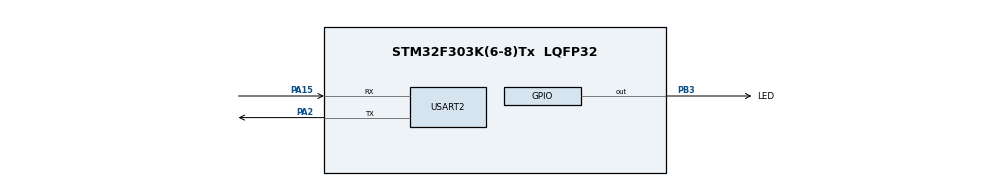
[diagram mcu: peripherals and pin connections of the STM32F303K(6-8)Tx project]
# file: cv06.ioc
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Mcu.Family=STM32F3
Mcu.Name=STM32F303K(6-8)Tx
Mcu.Package=LQFP32
NVIC.PriorityGroup=NVIC_PRIORITYGROUP_4
NVIC.USART2_IRQn=true\:0\:0\:false\:false\:true\:true\:true
PA15.Mode=Asynchronous
PA15.Signal=USART2_RX
PA2.Mode=Asynchronous
PA2.Signal=USART2_TX
PB3.GPIO_Label=LED
PB3.Signal=GPIO_Output
ProjectManager.HeapSize=0x200
ProjectManager.StackSize=0x400
ProjectManager.TargetToolchain=STM32CubeIDE
RCC.AHBFreq_Value=8000000
RCC.APB1Freq_Value=8000000
RCC.APB2Freq_Value=8000000
RCC.CortexFreq_Value=8000000
RCC.HSE_VALUE=8000000
RCC.HSI_VALUE=8000000
RCC.SYSCLKFreq_VALUE=8000000
USART2.VirtualMode-Asynchronous=VM_ASYNC
board=custom

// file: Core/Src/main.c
/* USER CODE BEGIN Header */
/**
  ******************************************************************************
  * @file           : main.c
  * @brief          : Main program body
  ******************************************************************************
  * @attention
  *
  * <h2><center>&copy; Copyright (c) 2021 STMicroelectronics.
  * All rights reserved.</center></h2>
  *
  * This software component is licensed by ST under BSD 3-Clause license,
  * the "License"; You may not use this file except in compliance with the
  * License. You may obtain a copy of the License at:
  *                        opensource.org/licenses/BSD-3-Clause
  *
  ******************************************************************************
  */
/* USER CODE END Header */
#include "main.h"
#include "usart.h"
#include "gpio.h"

/* USER CODE BEGIN Includes */
#include "stm32f3xx_it.h"
#include "string.h"
/* USER CODE END Includes */

/* USER CODE BEGIN PD */
#define MAX_COMMAND_LENGTH 6
/* USER CODE END PD */

/* USER CODE BEGIN PV */
volatile uint8_t command[MAX_COMMAND_LENGTH];
volatile int n=0;
/* USER CODE END PV */

void SystemClock_Config(void);
/* USER CODE BEGIN PFP */
void process_serial_data(uint8_t ch);
void usart_send_data(uint8_t* data, uint8_t length);
/* USER CODE END PFP */

int main(void)
{

  /* MCU Configuration--------------------------------------------------------*/

  /* Reset of all peripherals, Initializes the Flash interface and the Systick. */

  LL_APB2_GRP1_EnableClock(LL_APB2_GRP1_PERIPH_SYSCFG);
  LL_APB1_GRP1_EnableClock(LL_APB1_GRP1_PERIPH_PWR);

  NVIC_SetPriorityGrouping(NVIC_PRIORITYGROUP_4);

  /* System interrupt init*/
  /* SysTick_IRQn interrupt configuration */
  NVIC_SetPriority(SysTick_IRQn, NVIC_EncodePriority(NVIC_GetPriorityGrouping(),15, 0));

  /* Configure the system clock */
  SystemClock_Config();

  /* Initialize all configured peripherals */
  MX_GPIO_Init();
  MX_USART2_UART_Init();
  /* USER CODE BEGIN 2 */
  USART2_RegisterCallback(process_serial_data);
  LL_USART_EnableIT_RXNE(USART2);
  /* USER CODE END 2 */

  /* Infinite loop */
  while (1)
  {
	  if(LL_GPIO_IsOutputPinSet(LED_GPIO_Port, LED_Pin))
	  {
		  usart_send_data("LED ON\n", 7);
	  }
	  else
	  {
		  usart_send_data("LED OFF\n", 8);
	  }

	  LL_mDelay(5000);
  }
}

void SystemClock_Config(void)
{
  LL_FLASH_SetLatency(LL_FLASH_LATENCY_0);
  while(LL_FLASH_GetLatency()!= LL_FLASH_LATENCY_0)
  {
  }
  LL_RCC_HSI_Enable();

   /* Wait till HSI is ready */
  while(LL_RCC_HSI_IsReady() != 1)
  {

  }
  LL_RCC_HSI_SetCalibTrimming(16);
  LL_RCC_SetAHBPrescaler(LL_RCC_SYSCLK_DIV_1);
  LL_RCC_SetAPB1Prescaler(LL_RCC_APB1_DIV_1);
  LL_RCC_SetAPB2Prescaler(LL_RCC_APB2_DIV_1);
  LL_RCC_SetSysClkSource(LL_RCC_SYS_CLKSOURCE_HSI);

   /* Wait till System clock is ready */
  while(LL_RCC_GetSysClkSource() != LL_RCC_SYS_CLKSOURCE_STATUS_HSI)
  {

  }
  LL_Init1msTick(8000000);
  LL_SetSystemCoreClock(8000000);
}

/* USER CODE BEGIN 4 */
void process_serial_data(uint8_t ch)
{
	if ((ch=='\n') || (ch=='\r') || (ch=='\0'))
		return;

	if (ch=='l')
	{
		n=0;
		memset(command, 0, 6);
	}
	command[n]=ch;
	n++;

	if (strncmp(command, "ledON", 5)==0)
	{
		LL_GPIO_SetOutputPin(LED_GPIO_Port, LED_Pin);
	}

	if (strncmp(command, "ledOFF", 6)==0)
	{
		LL_GPIO_ResetOutputPin(LED_GPIO_Port, LED_Pin);
	}

	// reset n back to 0 if command length is exceeded
	n = n % MAX_COMMAND_LENGTH;

}

void usart_send_data(uint8_t* data, uint8_t length)
{
	for(uint8_t i = 0; i < length; ++i)
	{
		LL_USART_TransmitData8(USART2, data[i]);
		LL_mDelay(1);
	}
}
/* USER CODE END 4 */

void Error_Handler(void)
{
  __disable_irq();
  while (1)
  {
  }
}

/************************ (C) COPYRIGHT STMicroelectronics *****END OF FILE****/
